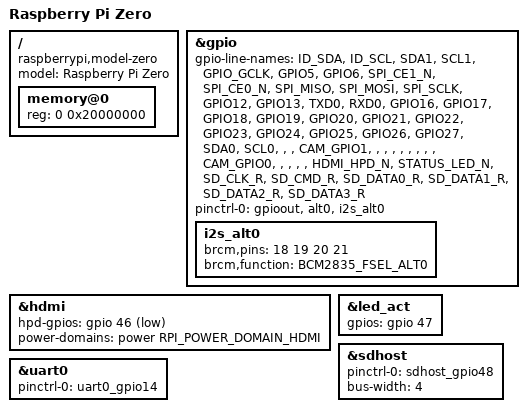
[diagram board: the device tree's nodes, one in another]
/dts-v1/;
#include "bcm2835.dtsi"
#include "bcm2835-rpi.dtsi"
#include "bcm2835-rpi-common.dtsi"
#include "bcm283x-rpi-led-deprecated.dtsi"
#include "bcm283x-rpi-usb-otg.dtsi"
/ {
	compatible = "raspberrypi,model-zero", "brcm,bcm2835";
	model = "Raspberry Pi Zero";
	memory@0 {
		device_type = "memory";
		reg = <0 0x20000000>;
	};
};
&gpio {
	gpio-line-names = "ID_SDA",
			  "ID_SCL",
			  "SDA1",
			  "SCL1",
			  "GPIO_GCLK",
			  "GPIO5",
			  "GPIO6",
			  "SPI_CE1_N",
			  "SPI_CE0_N",
			  "SPI_MISO",
			  "SPI_MOSI",
			  "SPI_SCLK",
			  "GPIO12",
			  "GPIO13",
			  "TXD0",
			  "RXD0",
			  "GPIO16",
			  "GPIO17",
			  "GPIO18",
			  "GPIO19",
			  "GPIO20",
			  "GPIO21",
			  "GPIO22",
			  "GPIO23",
			  "GPIO24",
			  "GPIO25",
			  "GPIO26",
			  "GPIO27",
			  "SDA0",
			  "SCL0",
			  "",  
			  "",  
			  "CAM_GPIO1",  
			  "",  
			  "",  
			  "",  
			  "",  
			  "",  
			  "",  
			  "",  
			  "",  
			  "CAM_GPIO0",  
			  "",  
			  "",  
			  "",  
			  "",  
			  "HDMI_HPD_N",
			  "STATUS_LED_N",
			  "SD_CLK_R",
			  "SD_CMD_R",
			  "SD_DATA0_R",
			  "SD_DATA1_R",
			  "SD_DATA2_R",
			  "SD_DATA3_R";
	pinctrl-names = "default";
	pinctrl-0 = <&gpioout &alt0 &i2s_alt0>;
	i2s_alt0: i2s_alt0 {
		brcm,pins = <18 19 20 21>;
		brcm,function = <BCM2835_FSEL_ALT0>;
	};
};
&hdmi {
	hpd-gpios = <&gpio 46 GPIO_ACTIVE_LOW>;
	power-domains = <&power RPI_POWER_DOMAIN_HDMI>;
	status = "okay";
};
&led_act {
	gpios = <&gpio 47 GPIO_ACTIVE_HIGH>;
};
&sdhost {
	pinctrl-names = "default";
	pinctrl-0 = <&sdhost_gpio48>;
	bus-width = <4>;
	status = "okay";
};
&uart0 {
	pinctrl-names = "default";
	pinctrl-0 = <&uart0_gpio14>;
	status = "okay";
};
